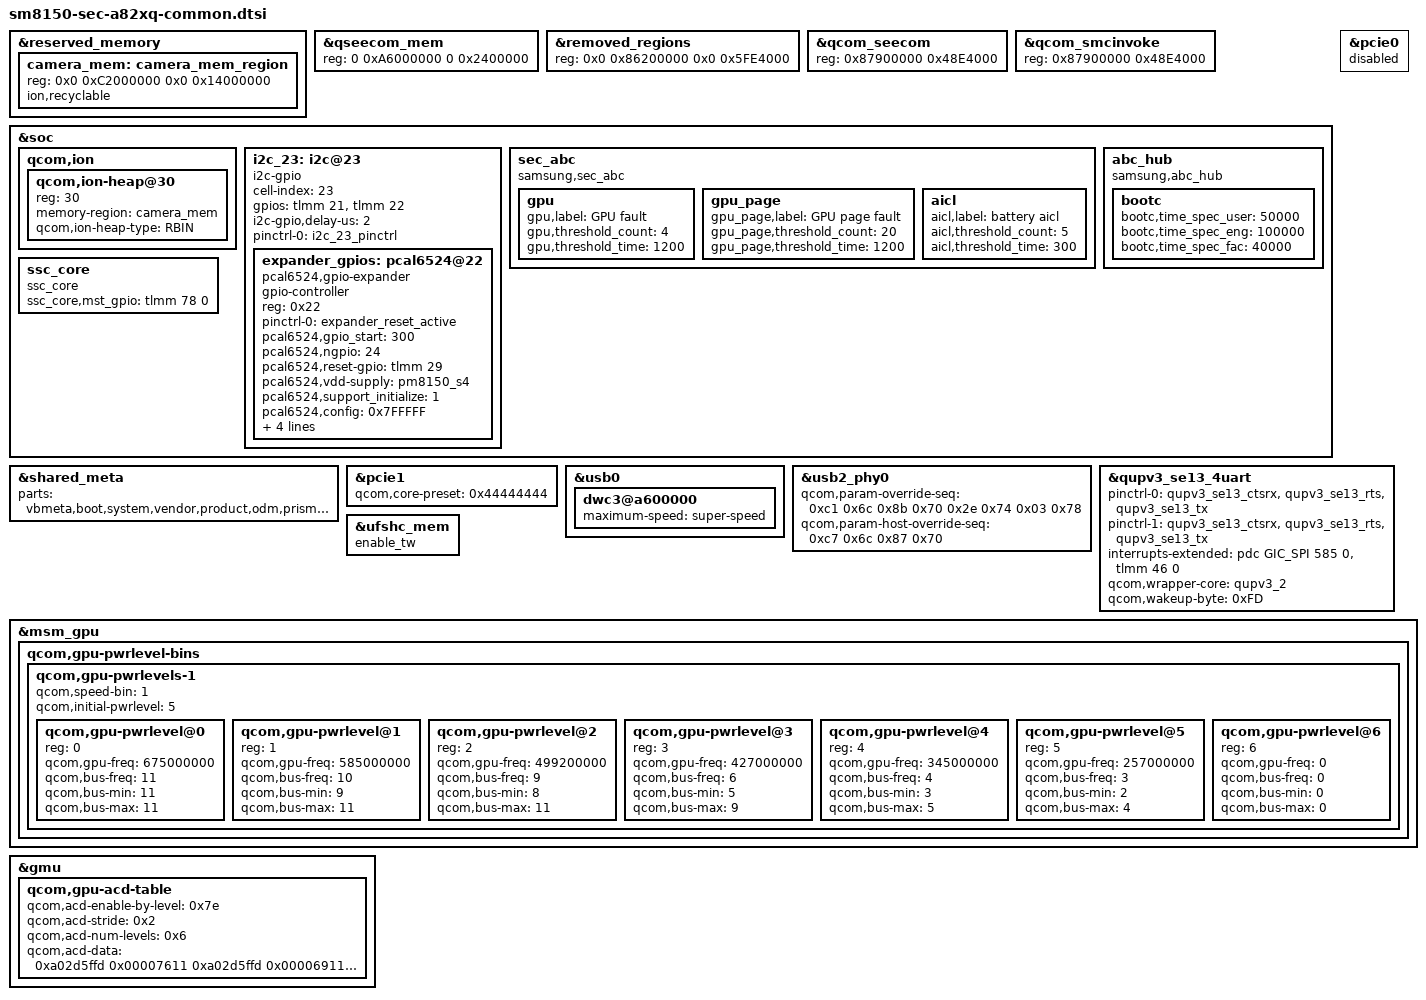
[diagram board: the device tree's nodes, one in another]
/* Copyright (c) 2016-2017, The Linux Foundation. All rights reserved.
 *
 * This program is free software; you can redistribute it and/or modify
 * it under the terms of the GNU General Public License version 2 and
 * only version 2 as published by the Free Software Foundation.
 *
 * This program is distributed in the hope that it will be useful,
 * but WITHOUT ANY WARRANTY; without even the implied warranty of
 * MERCHANTABILITY or FITNESS FOR A PARTICULAR PURPOSE.  See the
 * GNU General Public License for more details.
 */

#include "sm8150-sec-a82xq-vibrator-r00.dtsi"

&reserved_memory {
	camera_mem: camera_mem_region {
		reg = <0x0 0xC2000000 0x0 0x14000000>;
		ion,recyclable;
	};
};

&qseecom_mem {
	reg = <0 0xA6000000 0 0x2400000>;
};

/* TZapp region */
&removed_regions {
	reg = <0x0 0x86200000 0x0 0x5FE4000>;
};
/* only for compatibility, not used for qcom,appsbl-qseecom-support */
&qcom_seecom {
	reg = <0x87900000 0x48E4000>;
};
/* only for compatibility, there is no handling routine for reg in SMCinvoke driver */
&qcom_smcinvoke {
	reg = <0x87900000 0x48E4000>;
};

&soc {
	qcom,ion {
		qcom,ion-heap@30 { /* CAMERA HEAP  */
			reg = <30>;
			memory-region = <&camera_mem>;
			qcom,ion-heap-type = "RBIN";
		};
	};
};

&soc {
	i2c_23: i2c@23 {
		status = "ok";

		cell-index = <23>;
		compatible = "i2c-gpio";
		gpios = <&tlmm 21 0	/* EXPANDER_I2C_SDA_1P8 */
			 &tlmm 22 0	/* EXPANDER_I2C_SCL_1P8 */
		>;
		i2c-gpio,delay-us = <2>;
		#address-cells = <1>;
		#size-cells = <0>;

		pinctrl-names = "default";
		pinctrl-0 = <&i2c_23_pinctrl>;

		expander_gpios: pcal6524@22 {
			compatible = "pcal6524,gpio-expander";
			gpio-controller;
			#gpio-cells = <2>;
			reg = <0x22>;
			pinctrl-names = "expander_reset_setting";
			pinctrl-0 = <&expander_reset_active>;
			pcal6524,gpio_start = <300>;
			pcal6524,ngpio = <24>;
			pcal6524,reset-gpio = <&tlmm 29 0>;
			pcal6524,vdd-supply = <&pm8150_s4>;
			pcal6524,support_initialize = <1>;
			/* config, 24 ~ 0, 1bit configure[1:input, 0:output]*/
			pcal6524,config = <0x7FFFFF>;    /* P2[01111111] P1[11111111] P0[11111111] */
			/* data_out, 24 ~ 0, 1bit configure[1:high, 0:low]*/
			pcal6524,data_out = <0x000000>;  /* P2[00000000] P1[00000000] P0[00000000] */
			/* pull_reg, 8 ~ 0, 2bit configure[00:no_pull, 01:pull_down, 10:pull_up, 11:not used] */
			pcal6524,pull_reg_p0 = <0x0000>; /* 00 00 00 00 / 00 00 00 00 */
			pcal6524,pull_reg_p1 = <0x0000>; /* 00 00 00 00 / 00 00 00 00 */
			pcal6524,pull_reg_p2 = <0x0000>; /* 00 00 00 00 / 00 00 00 00 */
		};
	};

	sec_abc {
		compatible = "samsung,sec_abc";
		status = "okay";

		gpu {
			gpu,label="GPU fault";
			gpu,threshold_count=<4>;
			gpu,threshold_time=<1200>;
		};
		gpu_page {
			gpu_page,label="GPU page fault";
			gpu_page,threshold_count=<20>;
			gpu_page,threshold_time=<1200>;
		};
		aicl {
			aicl,label="battery aicl";
			aicl,threshold_count=<5>;
			aicl,threshold_time=<300>;
		};
	};

	abc_hub {
		compatible = "samsung,abc_hub";
		status = "okay";

		bootc {
			bootc,time_spec_user = <50000>; /* user binary user build */
			bootc,time_spec_eng = <100000>; /* user binary eng build */
			bootc,time_spec_fac = <40000>; /* factory binary */
		};

	};

	ssc_core {
		status = "okay";
		compatible = "ssc_core";
		ssc_core,mst_gpio = <&tlmm 78 0>;
	};
};

&shared_meta {
	status = "okay";
	parts = "vbmeta,boot,system,vendor,product,odm,prism,optics,vbmeta_system,recovery,dtbo,abl,xbl,tz,hyp";
};

&pcie0 {
	status = "disabled";
};

&pcie1 {
	qcom,core-preset = <0x44444444>;
};

&usb0 {
	dwc3@a600000 {
		maximum-speed = "super-speed";
	};
};

&usb2_phy0 {
	qcom,param-override-seq =
		<0xc1 0x6c
		 0x8b 0x70
		 0x2e 0x74
		 0x03 0x78>;
	qcom,param-host-override-seq =
		<0xc7 0x6c
		 0x87 0x70>;
};

&qupv3_se13_4uart {
	pinctrl-0 = <&qupv3_se13_ctsrx>, <&qupv3_se13_rts>,
					<&qupv3_se13_tx>;
	pinctrl-1 = <&qupv3_se13_ctsrx>, <&qupv3_se13_rts>,
					<&qupv3_se13_tx>;
	interrupts-extended = <&pdc GIC_SPI 585 0>,
			<&tlmm 46 0>;
	qcom,wrapper-core = <&qupv3_2>;
	qcom,wakeup-byte = <0xFD>;
	status = "ok";
};

&ufshc_mem {
	enable_tw;
};

/* gpu freq for SM8150 AC chipset*/
&msm_gpu {
	qcom,gpu-pwrlevel-bins {
		qcom,gpu-pwrlevels-1 {
			#address-cells = <1>;
			#size-cells = <0>;

			qcom,speed-bin = <1>;
			qcom,initial-pwrlevel = <5>;

			qcom,gpu-pwrlevel@0 {
				reg = <0>;
				qcom,gpu-freq = <675000000>;
				qcom,bus-freq = <11>;
				qcom,bus-min = <11>;
				qcom,bus-max = <11>;
			};

			qcom,gpu-pwrlevel@1 {
				reg = <1>;
				qcom,gpu-freq = <585000000>;
				qcom,bus-freq = <10>;
				qcom,bus-min = <9>;
				qcom,bus-max = <11>;
			};

			qcom,gpu-pwrlevel@2 {
				reg = <2>;
				qcom,gpu-freq = <499200000>;
				qcom,bus-freq = <9>;
				qcom,bus-min = <8>;
				qcom,bus-max = <11>;
			};

			qcom,gpu-pwrlevel@3 {
				reg = <3>;
				qcom,gpu-freq = <427000000>;
				qcom,bus-freq = <6>;
				qcom,bus-min = <5>;
				qcom,bus-max = <9>;
			};

			qcom,gpu-pwrlevel@4 {
				reg = <4>;
				qcom,gpu-freq = <345000000>;
				qcom,bus-freq = <4>;
				qcom,bus-min = <3>;
				qcom,bus-max = <5>;
			};

			qcom,gpu-pwrlevel@5 {
				reg = <5>;
				qcom,gpu-freq = <257000000>;
				qcom,bus-freq = <3>;
				qcom,bus-min = <2>;
				qcom,bus-max = <4>;
			};

			qcom,gpu-pwrlevel@6 {
				reg = <6>;
				qcom,gpu-freq = <0>;
				qcom,bus-freq = <0>;
				qcom,bus-min = <0>;
				qcom,bus-max = <0>;
			};
		};
	};
};

&gmu {
	qcom,gpu-acd-table {
		/* Corresponds to levels in the GPU perf table */
		qcom,acd-enable-by-level = <0x7e>;
		qcom,acd-stride = <0x2>;
		qcom,acd-num-levels = <0x6>;

		/* ACDCR, ACDTD */
		qcom,acd-data = <0xa02d5ffd 0x00007611 /* LowSVS */
				0xa02d5ffd 0x00006911 /* SVS */
				0xa02d5ffd 0x00006111 /* SVS_L1 */
				0xa02d5ffd 0x00006011 /* SVS_L2 */
				0x802d5ffd 0x00005411 /* NOM */
				0x802d5ffd 0x00005411>; /* NOM_L1 */
	};
};
